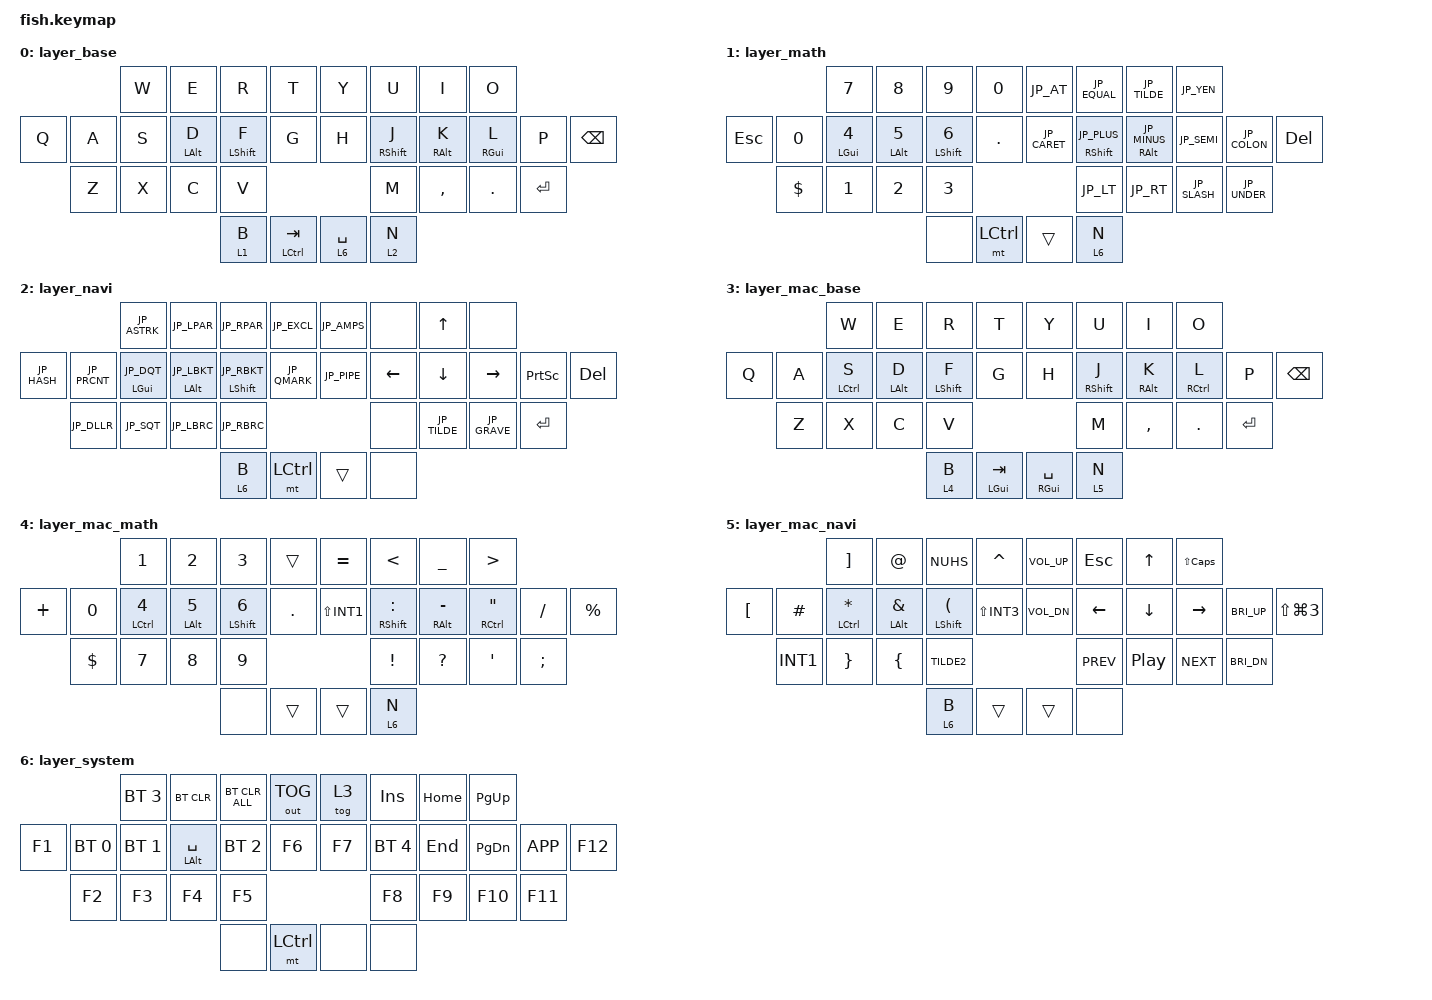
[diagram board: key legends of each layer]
// キーマップを更新する方法は https://o24.works/fish/guide を参照
// 視覚的に編集するには https://o24.works/fish/editor を参照


// 定義を呼んでくる
#include <behaviors.dtsi>
#include <dt-bindings/zmk/keys.h>
#include <dt-bindings/zmk/mouse.h>
#include <dt-bindings/zmk/bt.h>
#include <dt-bindings/zmk/outputs.h>
#include <dt-bindings/zmk/pointing.h>

#include "keycode_japanese.h"


// 特殊入力の挙動を調整できる

&mt {
    flavor = "tap-preferred";
    tapping-term-ms = <225>;
    quick-tap-ms = <200>;
    require-prior-idle-ms = <150>;
};

&lt {
    flavor = "balanced";
    tapping-term-ms = <175>;
    quick-tap-ms = <200>;
};

&sk {
};

&sl {
};

&caps_word {
};

&key_repeat {
};


/ {
    // 独自の入力を定義できる（上級者向け）

    behaviors {
    };

    macros {
    };

    conditional_layers {
    };


    // 複数キーの同時押しに特別の入力を設定できる
    // キー番号早見表：
    //       0  1  2  3     4  5  6  7
    // 8  9 10 11 12 13    14 15 16 17 18 19
    //   20 21 22 23          24 25 26 27
    //            28 29    30 31

    combos {
        compatible = "zmk,combos";
        timeout-ms = <100>;
        require-prior-idle-ms = <150>;

        combo_lang2 {
            key-positions = <21 22>;
            bindings = <&kp LANG2>;
        };

        combo_lang1 {
            key-positions = <25 26>;
            bindings = <&kp LANG1>;
        };

        combo_reset_L {
            key-positions = <3 8 13>;
            bindings = <&bootloader>;
        };

        combo_reset_R {
            key-positions = <4 14 19>;
            bindings = <&bootloader>;
        };
    };
    

    // キーに入力を割り当てる
    // 型（&...）は https://zmk.dev/docs/behaviors/... を参照
    // キーコードは https://zmk.dev/docs/codes/... を参照

    keymap {
        compatible = "zmk,keymap";

        layer_base {
            bindings = <
                        &kp W       &kp E       &kp R       &kp T               &kp Y       &kp U       &kp I       &kp O       
&kp Q       &kp A       &kp S       &mt LALT D  &mt LSHFT F &kp G               &kp H       &mt RSHFT J &mt RALT K  &mt RGUI L  &kp P       &kp BSPC    
            &kp Z       &kp X       &kp C       &kp V                                       &kp M       &kp COMMA   &kp DOT     &kp RET     
                                                &lt 1 B     &mt LCTRL TAB       &lt 6 SPACE &lt 2 N 
            >;
        };

        layer_math {
            bindings = <
                        &kp N7      &kp N8      &kp N9      &kp N0              &kp JP_AT   &kp JP_EQUAL &kp JP_TILDE &kp JP_YEN    
&kp ESC     &kp N0      &mt LGUI N4 &mt LALT N5 &mt LSHFT N6 &kp DOT            &kp JP_CARET &mt RSHFT JP_PLUS &mt RALT JP_MINUS &kp JP_SEMI &kp JP_COLON &kp DEL   
            &kp DLLR    &kp N1      &kp N2      &kp N3                                      &kp JP_LT   &kp JP_RT   &kp JP_SLASH &kp JP_UNDER    
                                                &none       &mt LCTRL           &trans      &lt 6 N     
            >;
        };

        layer_navi {
            bindings = <
                        &kp JP_ASTRK  &kp JP_LPAR  &kp JP_RPAR  &kp JP_EXCL           &kp JP_AMPS &none      &kp UP      &none       
&kp JP_HASH &kp JP_PRCNT &mt LGUI JP_DQT &mt LALT JP_LBKT &mt LSHFT JP_RBKT &kp JP_QMARK &kp JP_PIPE &kp LEFT   &kp DOWN    &kp RIGHT   &kp PSCRN &kp DEL  
            &kp JP_DLLR &kp JP_SQT    &kp JP_LBRC    &kp JP_RBRC                              &none  &kp JP_TILDE &kp JP_GRAVE  &kp RET 
                                                &lt 6 B     &mt LCTRL           &trans      &none       
            >;
        };

        layer_mac_base {
            bindings = <
                        &kp W       &kp E       &kp R       &kp T               &kp Y       &kp U       &kp I       &kp O       
&kp Q       &kp A       &mt LCTRL S &mt LALT D  &mt LSHFT F &kp G               &kp H       &mt RSHFT J &mt RALT K  &mt RCTRL L &kp P       &kp BSPC    
            &kp Z       &kp X       &kp C       &kp V                                       &kp M       &kp COMMA   &kp DOT     &kp RET     
                                                &lt 4 B     &mt LGUI TAB        &mt RGUI SPACE &lt 5 N  
            >;
        };

        layer_mac_math {
            bindings = <
                        &kp N1      &kp N2      &kp N3      &trans              &kp EQUAL   &kp LT      &kp UNDER   &kp GT      
&kp PLUS    &kp N0      &mt LCTRL N4 &mt LALT N5 &mt LSHFT N6 &kp DOT           &kp LS(INT1) &mt RSHFT COLON &mt RALT MINUS &mt RCTRL DQT &kp FSLH &kp PRCNT 
            &kp DLLR    &kp N7      &kp N8      &kp N9                                      &kp EXCL    &kp QMARK   &kp SQT     &kp SEMI    
                                                &none       &trans              &trans      &lt 6 N     
            >;
        };

        layer_mac_navi {
            bindings = <
                        &kp RBKT    &kp AT      &kp NUHS    &kp CARET           &kp C_VOL_UP &kp ESC    &kp UP      &kp LS(CAPS) 
&kp LBKT    &kp HASH    &mt LCTRL STAR &mt LALT AMPS &mt LSHFT LPAR &kp LS(INT3) &kp C_VOL_DN &kp LEFT  &kp DOWN    &kp RIGHT   &kp C_BRI_UP &kp LS(LG(N3)) 
            &kp INT1    &kp RBRC    &kp LBRC    &kp TILDE2                                  &kp C_PREV  &kp C_PP    &kp C_NEXT  &kp C_BRI_DN 
                                                &lt 6 B     &trans              &trans      &none       
            >;
        };

        layer_system {
            bindings = <
                        &bt BT_SEL 3 &bt BT_CLR &bt BT_CLR_ALL &out OUT_TOG     &tog 3      &kp INS     &kp HOME    &kp PG_UP   
&kp F1      &bt BT_SEL 0 &bt BT_SEL 1 &mt LALT SPACE &bt BT_SEL 2 &kp F6        &kp F7      &bt BT_SEL 4     &kp END     &kp PG_DN   &kp K_APP   &kp F12     
            &kp F2      &kp F3      &kp F4      &kp F5                                      &kp F8      &kp F9      &kp F10     &kp F11     
                                                &none       &mt LCTRL           &none       &none       
            >;
        };
    };
};
